# N32H7xx register map
Vendor: Nationstech Ltd.; File version: 1.0
Registers are 32-bit, read-write, reset 0x0 unless marked. A register's access mark holds for its fields unless they carry their own. Offsets are from the block's base; [hi:lo] are bit positions; {n}, {i} and the like mark numbered series; 'fields as' and 'values as' point back to an identical list.

## COMP
Base 0x58004800
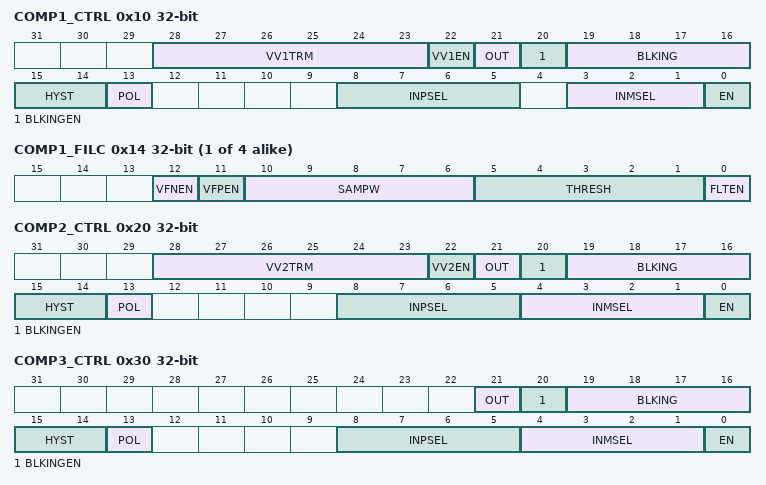
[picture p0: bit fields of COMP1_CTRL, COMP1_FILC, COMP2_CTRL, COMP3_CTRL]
0x10 COMP1_CTRL
  [28:23] VV1TRM, [22] VV1EN, [21] OUT, [20] BLKINGEN, [19:16] BLKING, [15:14] HYST, [13] POL, [8:5] INPSEL, [3:1] INMSEL, [0] EN
{0x4+0x10*i} COMP{i}_FILC (i=1..4)
  [12] VFNEN, [11] VFPEN, [10:6] SAMPW, [5:1] THRESH, [0] FLTEN
{0x8+0x10*i} COMP{i}_FILP (i=1..4)
  [15:0] CLKPSC
0x20 COMP2_CTRL
  [28:23] VV2TRM, [22] VV2EN, [21] OUT, [20] BLKINGEN, [19:16] BLKING, [15:14] HYST, [13] POL, [8:5] INPSEL, [4:1] INMSEL, [0] EN
0x30 COMP3_CTRL
  [21] OUT, [20] BLKINGEN, [19:16] BLKING, [15:14] HYST, [13] POL, [8:5] INPSEL, [4:1] INMSEL, [0] EN
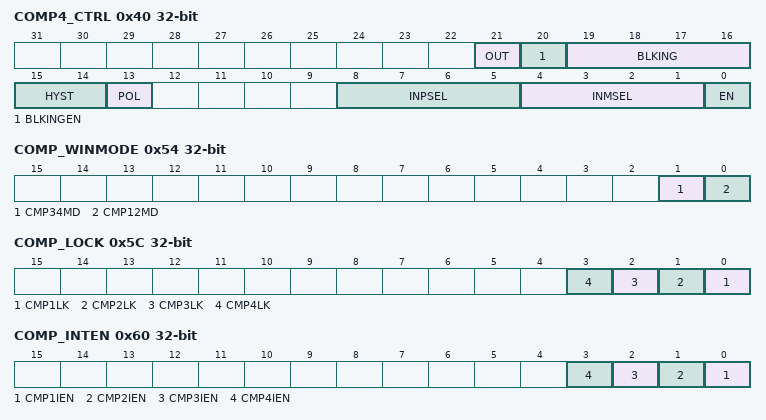
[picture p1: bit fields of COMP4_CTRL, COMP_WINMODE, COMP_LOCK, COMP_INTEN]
0x40 COMP4_CTRL
  fields as COMP3_CTRL
0x50 COMP_LPMODE
  [0] LPEN
0x54 COMP_WINMODE
  [1] CMP34MD, [0] CMP12MD
0x5C COMP_LOCK
  [n-1] CMP{n}LK (n=1..4)
0x60 COMP_INTEN
  [n-1] CMP{n}IEN (n=1..4)
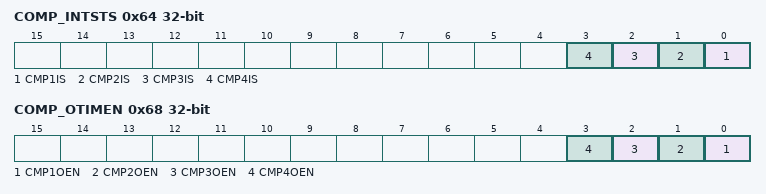
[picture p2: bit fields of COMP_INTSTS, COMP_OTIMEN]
0x64 COMP_INTSTS ro
  [n-1] CMP{n}IS (n=1..4)
0x68 COMP_OTIMEN
  [n-1] CMP{n}OEN (n=1..4)

## GPIOA — Genera Purpose I/O
Base 0x58032800
Same registers: GPIOB 0x58032C00, GPIOC 0x58033000, GPIOD 0x58033400, GPIOE 0x58033800, GPIOF 0x58033C00, GPIOG 0x58034000, GPIOH 0x58034400, GPIOI 0x58034800, GPIOJ 0x58034C00, GPIOK 0x58035000
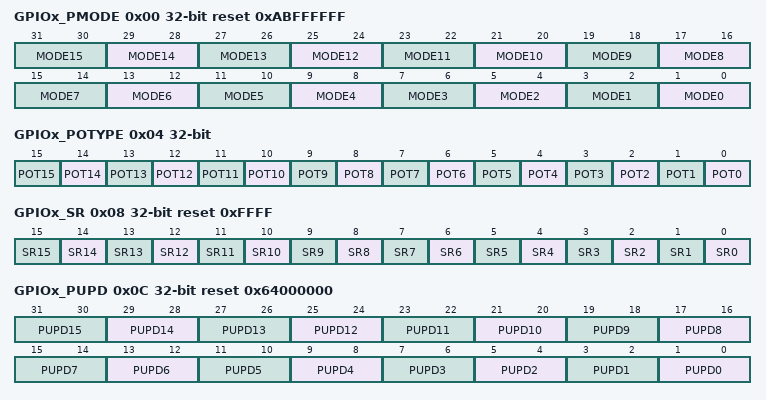
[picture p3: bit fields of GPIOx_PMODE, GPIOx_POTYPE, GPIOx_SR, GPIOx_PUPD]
0x00 GPIOx_PMODE reset 0xABFFFFFF — GPIO mode description register
  [2n+1:2n] MODE{n} (n=0..15)
0x04 GPIOx_POTYPE — GPIO type defenition
  [n] POT{n} (n=0..15)
0x08 GPIOx_SR reset 0xFFFF — Portx slew rate config register
  [n] SR{n} (n=0..15)
0x0C GPIOx_PUPD reset 0x64000000 — GPIO pull up pull down description register
  [2n+1:2n] PUPD{n} (n=0..15)
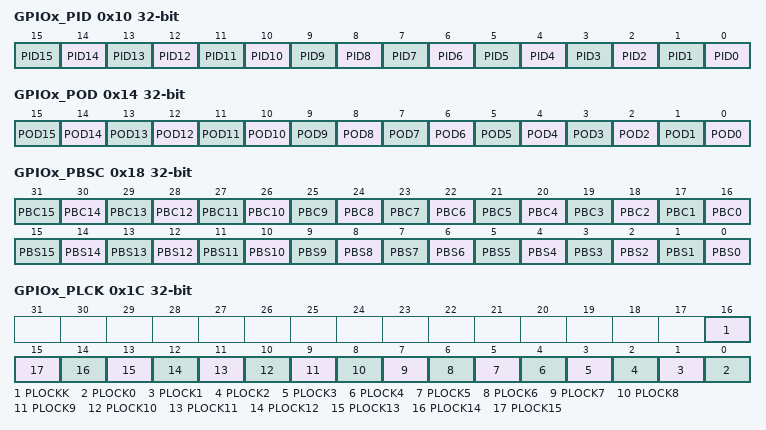
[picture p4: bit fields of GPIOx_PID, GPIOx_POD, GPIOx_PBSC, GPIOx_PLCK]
0x10 GPIOx_PID — GPIO input data register
  [n] PID{n} (n=0..15)
0x14 GPIOx_POD — GPIO output data register
  [n] POD{n} (n=0..15)
0x18 GPIOx_PBSC — Portx bit set/reset register
  [n+16] PBC{n} (n=0..15), [n] PBS{n} (n=0..15)
0x1C GPIOx_PLCK — Portx configuration lock register
  [16] PLOCKK, [n] PLOCK{n} (n=0..15)
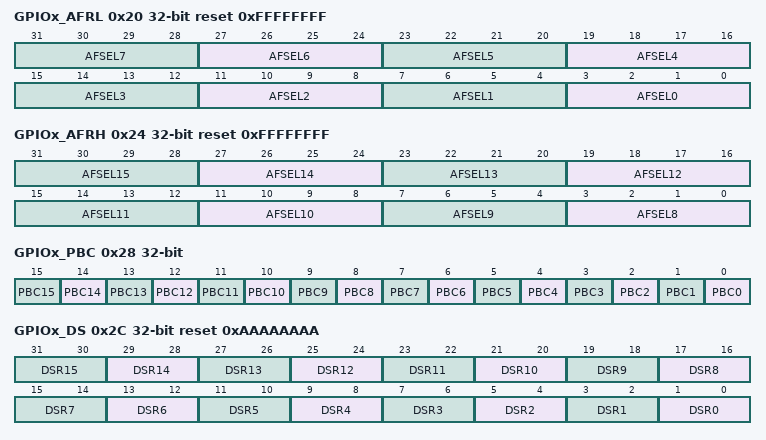
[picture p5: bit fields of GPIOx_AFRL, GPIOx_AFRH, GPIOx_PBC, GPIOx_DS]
0x20 GPIOx_AFRL reset 0xFFFFFFFF — Portx Alternate function low register
  [4n+3:4n] AFSEL{n} (n=0..7)
0x24 GPIOx_AFRH reset 0xFFFFFFFF — Portx Alternate function High register
  [4n-29:4n-32] AFSEL{n} (n=8..15)
0x28 GPIOx_PBC — Portx bit reset register
  [n] PBC{n} (n=0..15)
0x2C GPIOx_DS reset 0xAAAAAAAA — Portx driver strength config register
  [2n+1:2n] DSR{n} (n=0..15)

## EXTI — The Extended Interrupt and Event Controller
Base 0x58000000
0x00 EXTI_RT_CFG0 — Rising Edge Trigger Selection Register
  [31:0] RT_CFG0x
0x04 EXTI_RT_CFG1 — Rising Edge Trigger Selection Register
  [19:0] RT_CFG1x
0x20 EXTI_FT_CFG0 — Falling Edge Trigger Selection Register
  [31:0] FT_CFG0x
0x24 EXTI_FT_CFG1 — Falling Edge Trigger Selection Register
  [19:0] FT_CFG1x
0x40 EXTI_SWIE0 — Software Interrupt Enable Register
  [31:0] SWIE0x
0x44 EXTI_SWIE1 — Software Interrupt Enable Register
  [19:0] SWIE1x
0x60 EXTI_M7IMASK0 — EXTI to CPU0 interrupt mask register
  [31:0] M7IMSK0x
0x64 EXTI_M7IMASK1 — EXTI to CPU0 interrupt mask register
  [19:0] M7IMSK1x
0x80 EXTI_M4IMASK0 — EXTI to CPU1 interrupt mask register
  [31:0] M4IMSK0x
0x84 EXTI_M4IMASK1 — EXTI to CPU1 interrupt mask register
  [19:0] M4IMSK1x
0xA0 EXTI_M7EMASK0 — EXTI to CPU0 interrupt mask register
  [31:0] M7EMASK0x
0xA4 EXTI_M7EMASK1 — EXTI to CPU0 interrupt mask register
  [19:0] M7EMASK1x
0xC0 EXTI_M4EMASK0 — EXTI to CPU1 interrupt mask register
  [31:0] M4EMASK0x
0xC4 EXTI_M4EMASK1 — EXTI to CPU1 interrupt mask register
  [19:0] M4EMASK1x
0xE0 EXTI_M7PEND0 — EXTI CPU0 Pending Register
  [31:0] M7PEND0x
0xE4 EXTI_M7PEND1 — EXTI CPU0 Pending Register
  [19:0] M7PEND1x
0x100 EXTI_M4PEND0 — EXTI CPU1 Pending Register
  [31:0] M4PEND0x
0x104 EXTI_M4PEND1 — EXTI CPU1 Pending Register
  [19:0] M4PEND1x
0x120 EXTI_M7IMASK0_DRC — EXTI to CPU0 interrupt mask register
  [31:0] M7IMASK0_DRCx
0x124 EXTI_M7IMASK1_DRC — EXTI to CPU0 interrupt mask register
  [26:0] M7IMASK1_DRCx
0x140 EXTI_M4IMASK0_DRC — EXTI to CPU1 interrupt mask register
  [31:0] M4IMASK0_DRCx
0x144 EXTI_M4IMASK1_DRC — EXTI to CPU1 interrupt mask register
  [26:0] M4IMASK1_DRCx
0x160 EXTI_M7EMASK0_DRC — EXTI to CPU0 event mask register
  [31:0] M7EMASK0_DRCx
0x164 EXTI_M7EMASK1_DRC — EXTI to CPU0 event mask register
  [26:0] M7EMASK1_DRCx
0x180 EXTI_M4EMASK0_DRC — EXTI to CPU1 event mask register
  [31:0] M4EMASK0_DRCx
0x184 EXTI_M4EMASK1_DRC — EXTI to CPU1 event mask register
  [26:0] M4EMASK1_DRCx
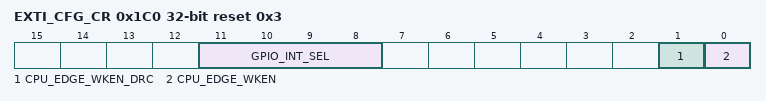
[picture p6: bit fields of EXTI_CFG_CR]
0x1C0 EXTI_CFG_CR reset 0x3 — EXTI to CPU1 event mask register
  [11:8] GPIO_INT_SEL, [1] CPU_EDGE_WKEN_DRC, [0] CPU_EDGE_WKEN
